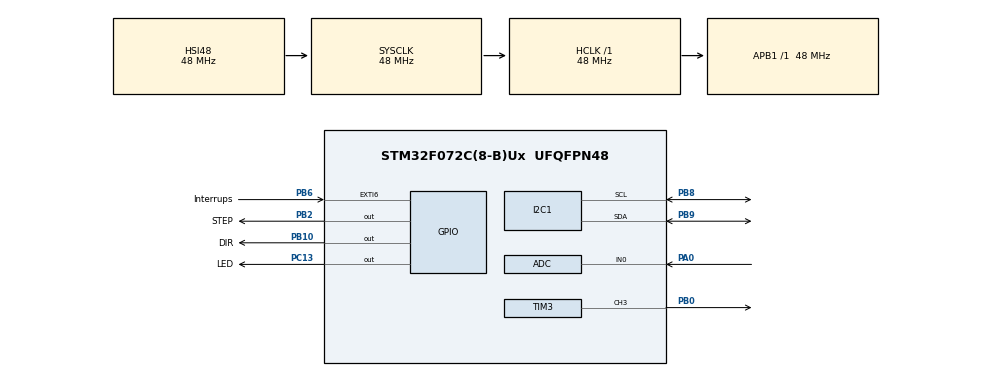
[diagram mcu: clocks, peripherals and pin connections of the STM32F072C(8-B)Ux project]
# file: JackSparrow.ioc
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ADC.ContinuousConvMode=ENABLE
ADC.DMAContinuousRequests=ENABLE
ADC.SamplingTime=ADC_SAMPLETIME_239CYCLES_5
Dma.ADC.0.Direction=DMA_PERIPH_TO_MEMORY
Dma.ADC.0.Instance=DMA1_Channel1
Dma.ADC.0.MemDataAlignment=DMA_MDATAALIGN_HALFWORD
Dma.ADC.0.MemInc=DMA_MINC_ENABLE
Dma.ADC.0.Mode=DMA_CIRCULAR
Dma.ADC.0.PeriphDataAlignment=DMA_PDATAALIGN_HALFWORD
Dma.ADC.0.PeriphInc=DMA_PINC_DISABLE
Dma.ADC.0.Priority=DMA_PRIORITY_LOW
Dma.Request0=ADC
Dma.Request1=TIM3_CH3
Dma.TIM3_CH3.1.Direction=DMA_MEMORY_TO_PERIPH
Dma.TIM3_CH3.1.Instance=DMA1_Channel2
Dma.TIM3_CH3.1.MemDataAlignment=DMA_MDATAALIGN_WORD
Dma.TIM3_CH3.1.MemInc=DMA_MINC_ENABLE
Dma.TIM3_CH3.1.Mode=DMA_CIRCULAR
Dma.TIM3_CH3.1.PeriphDataAlignment=DMA_PDATAALIGN_WORD
Dma.TIM3_CH3.1.PeriphInc=DMA_PINC_DISABLE
Dma.TIM3_CH3.1.Priority=DMA_PRIORITY_LOW
Mcu.Family=STM32F0
Mcu.Name=STM32F072C(8-B)Ux
Mcu.Package=UFQFPN48
NVIC.DMA1_Channel1_IRQn=true\:0\:0\:false\:false\:true\:false\:true\:false
NVIC.DMA1_Channel2_3_IRQn=true\:0\:0\:false\:false\:true\:false\:true\:true
NVIC.EXTI4_15_IRQn=true\:0\:0\:false\:false\:true\:true\:true\:true
NVIC.TIM2_IRQn=true\:0\:0\:false\:false\:true\:true\:true\:true
PA0.Mode=IN0
PA0.Signal=ADC_IN0
PA13.Mode=Serial_Wire
PA13.Signal=SYS_SWDIO
PA14.Mode=Serial_Wire
PA14.Signal=SYS_SWCLK
PB0.GPIO_ModeDefaultPP=GPIO_MODE_AF_OD
PB0.GPIO_Speed=GPIO_SPEED_FREQ_HIGH
PB0.Signal=S_TIM3_CH3
PB10.GPIO_Label=DIR
PB10.Signal=GPIO_Output
PB2.GPIO_Label=STEP
PB2.Signal=GPIO_Output
PB6.GPIO_Label=Interrups
PB6.Signal=GPXTI6
PB8.Mode=I2C
PB8.Signal=I2C1_SCL
PB9.Mode=I2C
PB9.Signal=I2C1_SDA
PC13.GPIO_Label=LED
PC13.Signal=GPIO_Output
PF0-OSC_IN.Mode=HSE-External-Oscillator
PF0-OSC_IN.Signal=RCC_OSC_IN
PF1-OSC_OUT.Mode=HSE-External-Oscillator
PF1-OSC_OUT.Signal=RCC_OSC_OUT
ProjectManager.HeapSize=0x200
ProjectManager.StackSize=0x400
ProjectManager.TargetToolchain=STM32CubeIDE
RCC.AHBFreq_Value=48000000
RCC.APB1Freq_Value=48000000
RCC.APB1TimFreq_Value=48000000
RCC.HCLKFreq_Value=48000000
RCC.HSE_VALUE=25000000
RCC.PLLSourceVirtual=RCC_PLLSOURCE_HSE
RCC.SYSCLKFreq_VALUE=48000000
RCC.SYSCLKSource=RCC_SYSCLKSOURCE_HSI48
SH.S_TIM3_CH3.0=TIM3_CH3,PWM Generation3 CH3
TIM2.Period=20000
TIM3.Channel-PWM\ Generation3\ CH3=TIM_CHANNEL_3
VP_TIM2_VS_ClockSourceINT.Mode=Internal
VP_TIM3_VS_ClockSourceINT.Mode=Internal
board=custom

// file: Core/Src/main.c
/* USER CODE BEGIN Header */
/**
  ******************************************************************************
  * @file           : main.c
  * @brief          : Main program body
  ******************************************************************************
  * @attention
  *
  * Copyright (c) 2024 STMicroelectronics.
  * All rights reserved.
  *
  * This software is licensed under terms that can be found in the LICENSE file
  * in the root directory of this software component.
  * If no LICENSE file comes with this software, it is provided AS-IS.
  *
  ******************************************************************************
  */
/* USER CODE END Header */
#include "main.h"

/* USER CODE BEGIN Includes */
#include "work.hpp"
/* USER CODE END Includes */

ADC_HandleTypeDef hadc;
DMA_HandleTypeDef hdma_adc;

I2C_HandleTypeDef hi2c1;

TIM_HandleTypeDef htim2;
TIM_HandleTypeDef htim3;
DMA_HandleTypeDef hdma_tim3_ch3;

/* USER CODE BEGIN PV */
uint16_t adcBuf[10];
/* USER CODE END PV */

void SystemClock_Config(void);
static void MX_GPIO_Init(void);
static void MX_DMA_Init(void);
static void MX_ADC_Init(void);
static void MX_TIM3_Init(void);
static void MX_I2C1_Init(void);
static void MX_TIM2_Init(void);

int main(void)
{

  /* MCU Configuration--------------------------------------------------------*/

  /* Reset of all peripherals, Initializes the Flash interface and the Systick. */
  HAL_Init();

  /* Configure the system clock */
  SystemClock_Config();

  /* Initialize all configured peripherals */
  MX_GPIO_Init();
  MX_DMA_Init();
  MX_ADC_Init();
  MX_TIM3_Init();
  MX_I2C1_Init();
  MX_TIM2_Init();
  /* USER CODE BEGIN 2 */
  HAL_ADC_Start_DMA (&hadc, (uint32_t *)adcBuf, 10);
  doWork();
  /* USER CODE END 2 */

  /* Infinite loop */
  while (1)
  {

    /* USER CODE BEGIN 3 */
	  Work();
  }
  /* USER CODE END 3 */
}

void SystemClock_Config(void)
{
  RCC_OscInitTypeDef RCC_OscInitStruct = {0};
  RCC_ClkInitTypeDef RCC_ClkInitStruct = {0};
  RCC_PeriphCLKInitTypeDef PeriphClkInit = {0};

  /** Initializes the RCC Oscillators according to the specified parameters
  * in the RCC_OscInitTypeDef structure.
  */
  RCC_OscInitStruct.OscillatorType = RCC_OSCILLATORTYPE_HSI|RCC_OSCILLATORTYPE_HSI14
                              |RCC_OSCILLATORTYPE_HSI48;
  RCC_OscInitStruct.HSIState = RCC_HSI_ON;
  RCC_OscInitStruct.HSI48State = RCC_HSI48_ON;
  RCC_OscInitStruct.HSI14State = RCC_HSI14_ON;
  RCC_OscInitStruct.HSICalibrationValue = RCC_HSICALIBRATION_DEFAULT;
  RCC_OscInitStruct.HSI14CalibrationValue = 16;
  RCC_OscInitStruct.PLL.PLLState = RCC_PLL_NONE;
  if (HAL_RCC_OscConfig(&RCC_OscInitStruct) != HAL_OK)
  {
    Error_Handler();
  }

  /** Initializes the CPU, AHB and APB buses clocks
  */
  RCC_ClkInitStruct.ClockType = RCC_CLOCKTYPE_HCLK|RCC_CLOCKTYPE_SYSCLK
                              |RCC_CLOCKTYPE_PCLK1;
  RCC_ClkInitStruct.SYSCLKSource = RCC_SYSCLKSOURCE_HSI48;
  RCC_ClkInitStruct.AHBCLKDivider = RCC_SYSCLK_DIV1;
  RCC_ClkInitStruct.APB1CLKDivider = RCC_HCLK_DIV1;

  if (HAL_RCC_ClockConfig(&RCC_ClkInitStruct, FLASH_LATENCY_1) != HAL_OK)
  {
    Error_Handler();
  }
  PeriphClkInit.PeriphClockSelection = RCC_PERIPHCLK_I2C1;
  PeriphClkInit.I2c1ClockSelection = RCC_I2C1CLKSOURCE_HSI;
  if (HAL_RCCEx_PeriphCLKConfig(&PeriphClkInit) != HAL_OK)
  {
    Error_Handler();
  }
}

static void MX_ADC_Init(void)
{

  ADC_ChannelConfTypeDef sConfig = {0};

  /** Configure the global features of the ADC (Clock, Resolution, Data Alignment and number of conversion)
  */
  hadc.Instance = ADC1;
  hadc.Init.ClockPrescaler = ADC_CLOCK_ASYNC_DIV1;
  hadc.Init.Resolution = ADC_RESOLUTION_12B;
  hadc.Init.DataAlign = ADC_DATAALIGN_RIGHT;
  hadc.Init.ScanConvMode = ADC_SCAN_DIRECTION_FORWARD;
  hadc.Init.EOCSelection = ADC_EOC_SINGLE_CONV;
  hadc.Init.LowPowerAutoWait = DISABLE;
  hadc.Init.LowPowerAutoPowerOff = DISABLE;
  hadc.Init.ContinuousConvMode = ENABLE;
  hadc.Init.DiscontinuousConvMode = DISABLE;
  hadc.Init.ExternalTrigConv = ADC_SOFTWARE_START;
  hadc.Init.ExternalTrigConvEdge = ADC_EXTERNALTRIGCONVEDGE_NONE;
  hadc.Init.DMAContinuousRequests = ENABLE;
  hadc.Init.Overrun = ADC_OVR_DATA_PRESERVED;
  if (HAL_ADC_Init(&hadc) != HAL_OK)
  {
    Error_Handler();
  }

  /** Configure for the selected ADC regular channel to be converted.
  */
  sConfig.Channel = ADC_CHANNEL_0;
  sConfig.Rank = ADC_RANK_CHANNEL_NUMBER;
  sConfig.SamplingTime = ADC_SAMPLETIME_239CYCLES_5;
  if (HAL_ADC_ConfigChannel(&hadc, &sConfig) != HAL_OK)
  {
    Error_Handler();
  }

}

static void MX_I2C1_Init(void)
{

  hi2c1.Instance = I2C1;
  hi2c1.Init.Timing = 0x2000090E;
  hi2c1.Init.OwnAddress1 = 0;
  hi2c1.Init.AddressingMode = I2C_ADDRESSINGMODE_7BIT;
  hi2c1.Init.DualAddressMode = I2C_DUALADDRESS_DISABLE;
  hi2c1.Init.OwnAddress2 = 0;
  hi2c1.Init.OwnAddress2Masks = I2C_OA2_NOMASK;
  hi2c1.Init.GeneralCallMode = I2C_GENERALCALL_DISABLE;
  hi2c1.Init.NoStretchMode = I2C_NOSTRETCH_DISABLE;
  if (HAL_I2C_Init(&hi2c1) != HAL_OK)
  {
    Error_Handler();
  }

  /** Configure Analogue filter
  */
  if (HAL_I2CEx_ConfigAnalogFilter(&hi2c1, I2C_ANALOGFILTER_ENABLE) != HAL_OK)
  {
    Error_Handler();
  }

  /** Configure Digital filter
  */
  if (HAL_I2CEx_ConfigDigitalFilter(&hi2c1, 0) != HAL_OK)
  {
    Error_Handler();
  }

}

static void MX_TIM2_Init(void)
{

  TIM_ClockConfigTypeDef sClockSourceConfig = {0};
  TIM_MasterConfigTypeDef sMasterConfig = {0};

  htim2.Instance = TIM2;
  htim2.Init.Prescaler = 0;
  htim2.Init.CounterMode = TIM_COUNTERMODE_UP;
  htim2.Init.Period = 20000;
  htim2.Init.ClockDivision = TIM_CLOCKDIVISION_DIV1;
  htim2.Init.AutoReloadPreload = TIM_AUTORELOAD_PRELOAD_DISABLE;
  if (HAL_TIM_Base_Init(&htim2) != HAL_OK)
  {
    Error_Handler();
  }
  sClockSourceConfig.ClockSource = TIM_CLOCKSOURCE_INTERNAL;
  if (HAL_TIM_ConfigClockSource(&htim2, &sClockSourceConfig) != HAL_OK)
  {
    Error_Handler();
  }
  sMasterConfig.MasterOutputTrigger = TIM_TRGO_RESET;
  sMasterConfig.MasterSlaveMode = TIM_MASTERSLAVEMODE_DISABLE;
  if (HAL_TIMEx_MasterConfigSynchronization(&htim2, &sMasterConfig) != HAL_OK)
  {
    Error_Handler();
  }

}

static void MX_TIM3_Init(void)
{

  TIM_ClockConfigTypeDef sClockSourceConfig = {0};
  TIM_MasterConfigTypeDef sMasterConfig = {0};
  TIM_OC_InitTypeDef sConfigOC = {0};

  htim3.Instance = TIM3;
  htim3.Init.Prescaler = 0;
  htim3.Init.CounterMode = TIM_COUNTERMODE_UP;
  htim3.Init.Period = 65535;
  htim3.Init.ClockDivision = TIM_CLOCKDIVISION_DIV1;
  htim3.Init.AutoReloadPreload = TIM_AUTORELOAD_PRELOAD_DISABLE;
  if (HAL_TIM_Base_Init(&htim3) != HAL_OK)
  {
    Error_Handler();
  }
  sClockSourceConfig.ClockSource = TIM_CLOCKSOURCE_INTERNAL;
  if (HAL_TIM_ConfigClockSource(&htim3, &sClockSourceConfig) != HAL_OK)
  {
    Error_Handler();
  }
  if (HAL_TIM_PWM_Init(&htim3) != HAL_OK)
  {
    Error_Handler();
  }
  sMasterConfig.MasterOutputTrigger = TIM_TRGO_RESET;
  sMasterConfig.MasterSlaveMode = TIM_MASTERSLAVEMODE_DISABLE;
  if (HAL_TIMEx_MasterConfigSynchronization(&htim3, &sMasterConfig) != HAL_OK)
  {
    Error_Handler();
  }
  sConfigOC.OCMode = TIM_OCMODE_PWM1;
  sConfigOC.Pulse = 0;
  sConfigOC.OCPolarity = TIM_OCPOLARITY_HIGH;
  sConfigOC.OCFastMode = TIM_OCFAST_DISABLE;
  if (HAL_TIM_PWM_ConfigChannel(&htim3, &sConfigOC, TIM_CHANNEL_3) != HAL_OK)
  {
    Error_Handler();
  }
  HAL_TIM_MspPostInit(&htim3);

}

static void MX_DMA_Init(void)
{

  /* DMA controller clock enable */
  __HAL_RCC_DMA1_CLK_ENABLE();

  /* DMA interrupt init */
  /* DMA1_Channel1_IRQn interrupt configuration */
  HAL_NVIC_SetPriority(DMA1_Channel1_IRQn, 0, 0);
  HAL_NVIC_EnableIRQ(DMA1_Channel1_IRQn);
  /* DMA1_Channel2_3_IRQn interrupt configuration */
  HAL_NVIC_SetPriority(DMA1_Channel2_3_IRQn, 0, 0);
  HAL_NVIC_EnableIRQ(DMA1_Channel2_3_IRQn);

}

static void MX_GPIO_Init(void)
{
  GPIO_InitTypeDef GPIO_InitStruct = {0};

  /* GPIO Ports Clock Enable */
  __HAL_RCC_GPIOC_CLK_ENABLE();
  __HAL_RCC_GPIOF_CLK_ENABLE();
  __HAL_RCC_GPIOA_CLK_ENABLE();
  __HAL_RCC_GPIOB_CLK_ENABLE();

  /*Configure GPIO pin Output Level */
  HAL_GPIO_WritePin(LED_GPIO_Port, LED_Pin, GPIO_PIN_RESET);

  /*Configure GPIO pin Output Level */
  HAL_GPIO_WritePin(GPIOB, STEP_Pin|DIR_Pin, GPIO_PIN_RESET);

  /*Configure GPIO pin : LED_Pin */
  GPIO_InitStruct.Pin = LED_Pin;
  GPIO_InitStruct.Mode = GPIO_MODE_OUTPUT_PP;
  GPIO_InitStruct.Pull = GPIO_NOPULL;
  GPIO_InitStruct.Speed = GPIO_SPEED_FREQ_LOW;
  HAL_GPIO_Init(LED_GPIO_Port, &GPIO_InitStruct);

  /*Configure GPIO pins : STEP_Pin DIR_Pin */
  GPIO_InitStruct.Pin = STEP_Pin|DIR_Pin;
  GPIO_InitStruct.Mode = GPIO_MODE_OUTPUT_PP;
  GPIO_InitStruct.Pull = GPIO_NOPULL;
  GPIO_InitStruct.Speed = GPIO_SPEED_FREQ_LOW;
  HAL_GPIO_Init(GPIOB, &GPIO_InitStruct);

  /*Configure GPIO pin : Interrups_Pin */
  GPIO_InitStruct.Pin = Interrups_Pin;
  GPIO_InitStruct.Mode = GPIO_MODE_IT_RISING;
  GPIO_InitStruct.Pull = GPIO_NOPULL;
  HAL_GPIO_Init(Interrups_GPIO_Port, &GPIO_InitStruct);

  /* EXTI interrupt init*/
  HAL_NVIC_SetPriority(EXTI4_15_IRQn, 0, 0);
  HAL_NVIC_EnableIRQ(EXTI4_15_IRQn);

}

void Error_Handler(void)
{
  __disable_irq();
  while (1)
  {
  }
}
